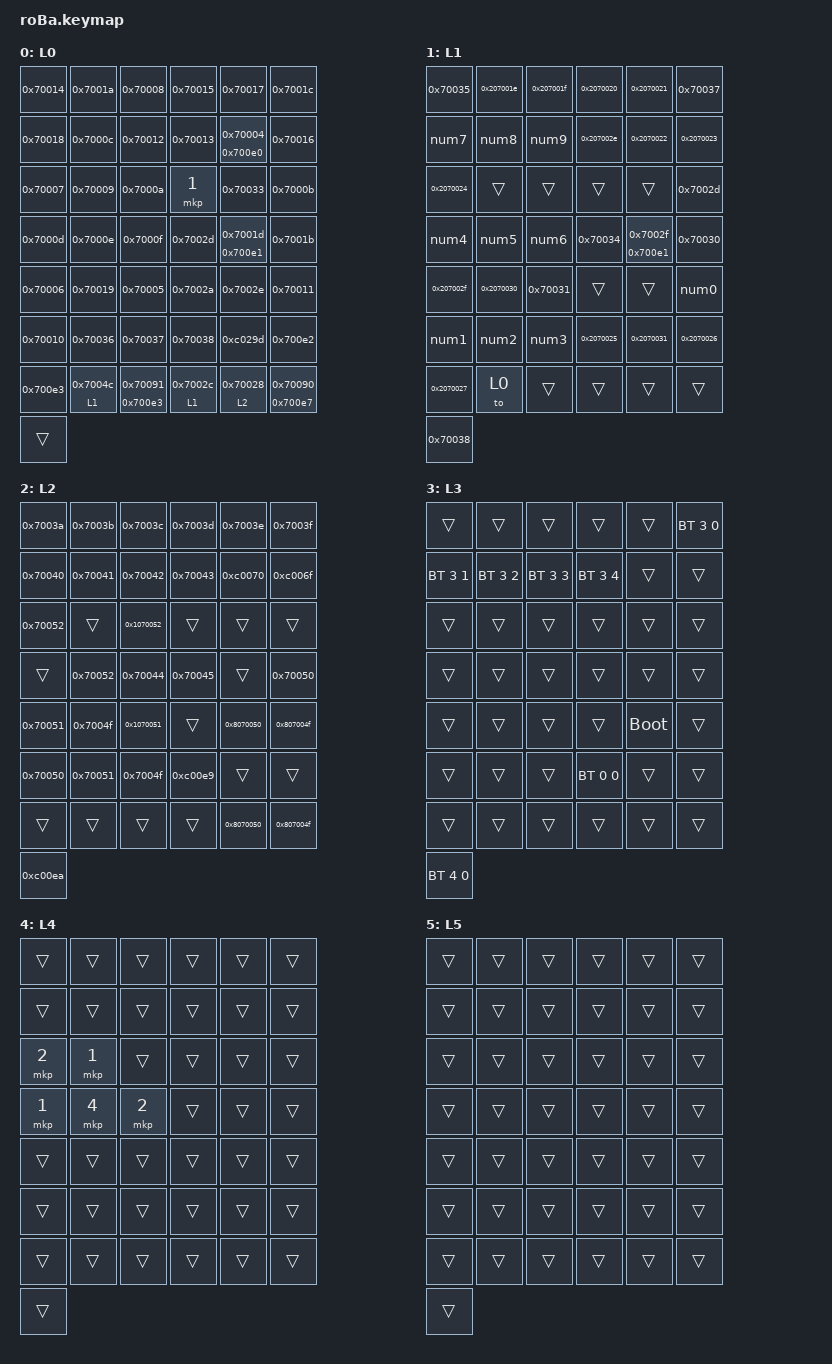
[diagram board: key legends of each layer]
/*
 * roBa (Low Profile) キーマップ
 * 出品者ファームウェア（~/src/roba-backup/right_seller.uf2）の設定と、
 * 2026-11-15 時点で ZMK Studio から読んだ配置をもとに tools/gen_keymap.py で作る。
 */
#include <behaviors.dtsi>
#include <dt-bindings/zmk/bt.h>
#include <dt-bindings/zmk/keys.h>
#include <dt-bindings/zmk/pointing.h>

/* 長押しの判定（出品者: 180 ms, tap-preferred, quick-tap 150 ms） */
&mt { flavor = "tap-preferred"; tapping-term-ms = <220>; quick-tap-ms = <150>; };
&lt { flavor = "tap-preferred"; tapping-term-ms = <220>; quick-tap-ms = <150>; };

&trackball {
    automouse-layer = <4>;
    scroll-layers = <5>;    /* D＋F・J＋K を押し続けている間はスクロール */
};

/ {
    behaviors {
        /* A・Z 用: 直前のキーから 150 ms 以内は必ず文字として扱う */
        mt_key: mt_key {
            compatible = "zmk,behavior-hold-tap";
            label = "MT_KEY";
            display-name = "Mod-Tap (文字キー)";
            #binding-cells = <2>;
            bindings = <&kp>, <&kp>;
            flavor = "tap-preferred";
            tapping-term-ms = <220>;
            quick-tap-ms = <150>;
            require-prior-idle-ms = <150>;
        };

        lt_to_layer_0: lt_to_layer_0 {
            compatible = "zmk,behavior-hold-tap";
            label = "LAYER_TAP_TO_0";
            display-name = "LAYER_TAP_TO_0";
            #binding-cells = <2>;
            bindings = <&mo>, <&to_layer_0>;
            flavor = "hold-preferred";
            tapping-term-ms = <180>;
        };

        /* D＋F・J＋K 用: 短く押すと Shift＋Tab・Enter、押し続けるとレイヤー 5（トラックボールでスクロール） */
        tap_scroll: tap_scroll {
            compatible = "zmk,behavior-hold-tap";
            label = "TAP_SCROLL";
            display-name = "キー / スクロール";
            #binding-cells = <2>;
            bindings = <&mo>, <&kp>;
            flavor = "hold-preferred";
            tapping-term-ms = <200>;
        };

        mouse_command: mouse_command {
            compatible = "zmk,behavior-hold-tap";
            label = "MOUSE_COMMAND";
            display-name = "MOUSE_COMMAND";
            #binding-cells = <2>;
            bindings = <&kp>, <&mkp>;
            flavor = "tap-preferred";
            tapping-term-ms = <180>;
        };

        alt_tab_rotate: alt_tab_rotate {
            compatible = "zmk,behavior-sensor-rotate";
            label = "ALT_TAB_ROTATE";
            #sensor-binding-cells = <0>;
            bindings = <&kp 0x0c070050>, <&kp 0x0c07004f>;
            tap-ms = <20>;
        };

        enc_msc_down_up: enc_msc_down_up {
            compatible = "zmk,behavior-sensor-rotate";
            label = "ENCODER_MSC_DOWN_UP";
            #sensor-binding-cells = <0>;
            bindings = <&msc MOVE_Y(-80)>, <&msc MOVE_Y(80)>;
            tap-ms = <20>;
        };

        enc_key_press: enc_key_press {
            compatible = "zmk,behavior-sensor-rotate-var";
            label = "enc_key_press";
            #sensor-binding-cells = <2>;
            bindings = <&kp>, <&kp>;
            tap-ms = <5>;
        };

        num0: num0 {
            compatible = "zmk,behavior-mod-morph";
            display-name = "数字0";
            #binding-cells = <0>;
            bindings = <&kp 0x70062>, <&kp 0x70027>;
            mods = <(MOD_LGUI|MOD_RGUI|MOD_LCTL|MOD_RCTL|MOD_LALT|MOD_RALT)>;
            keep-mods = <(MOD_LGUI|MOD_RGUI|MOD_LCTL|MOD_RCTL|MOD_LALT|MOD_RALT)>;
        };

        num1: num1 {
            compatible = "zmk,behavior-mod-morph";
            display-name = "数字1";
            #binding-cells = <0>;
            bindings = <&kp 0x70059>, <&kp 0x7001e>;
            mods = <(MOD_LGUI|MOD_RGUI|MOD_LCTL|MOD_RCTL|MOD_LALT|MOD_RALT)>;
            keep-mods = <(MOD_LGUI|MOD_RGUI|MOD_LCTL|MOD_RCTL|MOD_LALT|MOD_RALT)>;
        };

        num2: num2 {
            compatible = "zmk,behavior-mod-morph";
            display-name = "数字2";
            #binding-cells = <0>;
            bindings = <&kp 0x7005a>, <&kp 0x7001f>;
            mods = <(MOD_LGUI|MOD_RGUI|MOD_LCTL|MOD_RCTL|MOD_LALT|MOD_RALT)>;
            keep-mods = <(MOD_LGUI|MOD_RGUI|MOD_LCTL|MOD_RCTL|MOD_LALT|MOD_RALT)>;
        };

        num3: num3 {
            compatible = "zmk,behavior-mod-morph";
            display-name = "数字3";
            #binding-cells = <0>;
            bindings = <&kp 0x7005b>, <&kp 0x70020>;
            mods = <(MOD_LGUI|MOD_RGUI|MOD_LCTL|MOD_RCTL|MOD_LALT|MOD_RALT)>;
            keep-mods = <(MOD_LGUI|MOD_RGUI|MOD_LCTL|MOD_RCTL|MOD_LALT|MOD_RALT)>;
        };

        num4: num4 {
            compatible = "zmk,behavior-mod-morph";
            display-name = "数字4";
            #binding-cells = <0>;
            bindings = <&kp 0x7005c>, <&kp 0x70021>;
            mods = <(MOD_LGUI|MOD_RGUI|MOD_LCTL|MOD_RCTL|MOD_LALT|MOD_RALT)>;
            keep-mods = <(MOD_LGUI|MOD_RGUI|MOD_LCTL|MOD_RCTL|MOD_LALT|MOD_RALT)>;
        };

        num5: num5 {
            compatible = "zmk,behavior-mod-morph";
            display-name = "数字5";
            #binding-cells = <0>;
            bindings = <&kp 0x7005d>, <&kp 0x70022>;
            mods = <(MOD_LGUI|MOD_RGUI|MOD_LCTL|MOD_RCTL|MOD_LALT|MOD_RALT)>;
            keep-mods = <(MOD_LGUI|MOD_RGUI|MOD_LCTL|MOD_RCTL|MOD_LALT|MOD_RALT)>;
        };

        num6: num6 {
            compatible = "zmk,behavior-mod-morph";
            display-name = "数字6";
            #binding-cells = <0>;
            bindings = <&kp 0x7005e>, <&kp 0x70023>;
            mods = <(MOD_LGUI|MOD_RGUI|MOD_LCTL|MOD_RCTL|MOD_LALT|MOD_RALT)>;
            keep-mods = <(MOD_LGUI|MOD_RGUI|MOD_LCTL|MOD_RCTL|MOD_LALT|MOD_RALT)>;
        };

        num7: num7 {
            compatible = "zmk,behavior-mod-morph";
            display-name = "数字7";
            #binding-cells = <0>;
            bindings = <&kp 0x7005f>, <&kp 0x70024>;
            mods = <(MOD_LGUI|MOD_RGUI|MOD_LCTL|MOD_RCTL|MOD_LALT|MOD_RALT)>;
            keep-mods = <(MOD_LGUI|MOD_RGUI|MOD_LCTL|MOD_RCTL|MOD_LALT|MOD_RALT)>;
        };

        num8: num8 {
            compatible = "zmk,behavior-mod-morph";
            display-name = "数字8";
            #binding-cells = <0>;
            bindings = <&kp 0x70060>, <&kp 0x70025>;
            mods = <(MOD_LGUI|MOD_RGUI|MOD_LCTL|MOD_RCTL|MOD_LALT|MOD_RALT)>;
            keep-mods = <(MOD_LGUI|MOD_RGUI|MOD_LCTL|MOD_RCTL|MOD_LALT|MOD_RALT)>;
        };

        num9: num9 {
            compatible = "zmk,behavior-mod-morph";
            display-name = "数字9";
            #binding-cells = <0>;
            bindings = <&kp 0x70061>, <&kp 0x70026>;
            mods = <(MOD_LGUI|MOD_RGUI|MOD_LCTL|MOD_RCTL|MOD_LALT|MOD_RALT)>;
            keep-mods = <(MOD_LGUI|MOD_RGUI|MOD_LCTL|MOD_RCTL|MOD_LALT|MOD_RALT)>;
        };
    };

    macros {
        to_layer_0: to_layer_0 {
            compatible = "zmk,behavior-macro-one-param";
            label = "TO_LAYER_0";
            display-name = "TO_LAYER_0";
            #binding-cells = <1>;
            bindings = <&to 0 &macro_param_1to1 &kp MACRO_PLACEHOLDER>;
        };
    };

    /* BS（L1）と Enter（L2）を同時に長押しすると Bluetooth のレイヤー 3 */
    conditional_layers {
        compatible = "zmk,conditional-layers";
        bluetooth {
            if-layers = <1 2>;
            then-layer = <3>;
        };
    };

    /* 出品者の同時押し（50 ms 以内） */
    combos {
        compatible = "zmk,combos";
        esc { timeout-ms = <50>; key-positions = <0 1>; bindings = <&to_layer_0 ESCAPE>; };
        grave { timeout-ms = <50>; key-positions = <1 2>; bindings = <&kp GRAVE>; };
        excl { timeout-ms = <50>; key-positions = <2 3>; bindings = <&kp EXCLAMATION>; };
        at { timeout-ms = <50>; key-positions = <3 4>; bindings = <&kp AT_SIGN>; };
        lpar { timeout-ms = <50>; key-positions = <6 7>; bindings = <&kp LEFT_PARENTHESIS>; };
        rpar { timeout-ms = <50>; key-positions = <7 8>; bindings = <&kp RIGHT_PARENTHESIS>; };
        bspc { timeout-ms = <50>; key-positions = <8 9>; bindings = <&kp BACKSPACE>; };
        tab { timeout-ms = <50>; key-positions = <11 12>; bindings = <&kp TAB>; };
        shift_tab { timeout-ms = <50>; key-positions = <12 13>; bindings = <&tap_scroll 5 LS(TAB)>; };
        enter_jk { timeout-ms = <50>; key-positions = <18 19>; bindings = <&tap_scroll 5 ENTER>; };
        lbkt_kl { timeout-ms = <50>; key-positions = <19 20>; bindings = <&kp LEFT_BRACKET>; };
        rbkt_ld { timeout-ms = <50>; key-positions = <20 21>; bindings = <&kp RIGHT_BRACKET>; };
    };

    keymap {
        compatible = "zmk,keymap";

        layer_0 {
            display-name = "L0";
            bindings = <
                &kp 0x70014  &kp 0x7001a  &kp 0x70008  &kp 0x70015  &kp 0x70017  &kp 0x7001c
                &kp 0x70018  &kp 0x7000c  &kp 0x70012  &kp 0x70013  &mt_key 0x700e0 0x70004  &kp 0x70016
                &kp 0x70007  &kp 0x70009  &kp 0x7000a  &mkp 1  &kp 0x70033  &kp 0x7000b
                &kp 0x7000d  &kp 0x7000e  &kp 0x7000f  &kp 0x7002d  &mt_key 0x700e1 0x7001d  &kp 0x7001b
                &kp 0x70006  &kp 0x70019  &kp 0x70005  &kp 0x7002a  &kp 0x7002e  &kp 0x70011
                &kp 0x70010  &kp 0x70036  &kp 0x70037  &kp 0x70038  &kp 0xc029d  &kp 0x700e2
                &kp 0x700e3  &lt_to_layer_0 1 0x7004c  &mt 0x700e3 0x70091  &lt 1 0x7002c  &lt 2 0x70028  &mt 0x700e7 0x70090
                &trans
            >;
            sensor-bindings = <&enc_msc_down_up>;
        };

        layer_1 {
            display-name = "L1";
            bindings = <
                &kp 0x70035  &kp 0x207001e  &kp 0x207001f  &kp 0x2070020  &kp 0x2070021  &kp 0x70037
                &num7  &num8  &num9  &kp 0x207002e  &kp 0x2070022  &kp 0x2070023
                &kp 0x2070024  &trans  &trans  &trans  &trans  &kp 0x7002d
                &num4  &num5  &num6  &kp 0x70034  &mt 0x700e1 0x7002f  &kp 0x70030
                &kp 0x207002f  &kp 0x2070030  &kp 0x70031  &trans  &trans  &num0
                &num1  &num2  &num3  &kp 0x2070025  &kp 0x2070031  &kp 0x2070026
                &kp 0x2070027  &to 0  &trans  &trans  &trans  &trans
                &kp 0x70038
            >;
        };

        layer_2 {
            display-name = "L2";
            bindings = <
                &kp 0x7003a  &kp 0x7003b  &kp 0x7003c  &kp 0x7003d  &kp 0x7003e  &kp 0x7003f
                &kp 0x70040  &kp 0x70041  &kp 0x70042  &kp 0x70043  &kp 0xc0070  &kp 0xc006f
                &kp 0x70052  &trans  &kp 0x1070052  &trans  &trans  &trans
                &trans  &kp 0x70052  &kp 0x70044  &kp 0x70045  &trans  &kp 0x70050
                &kp 0x70051  &kp 0x7004f  &kp 0x1070051  &trans  &kp 0x8070050  &kp 0x807004f
                &kp 0x70050  &kp 0x70051  &kp 0x7004f  &kp 0xc00e9  &trans  &trans
                &trans  &trans  &trans  &trans  &kp 0x8070050  &kp 0x807004f
                &kp 0xc00ea
            >;
            sensor-bindings = <&enc_key_press 0xc00e9 0xc00ea>;
        };

        layer_3 {
            display-name = "L3";
            bindings = <
                &trans  &trans  &trans  &trans  &trans  &bt 3 0
                &bt 3 1  &bt 3 2  &bt 3 3  &bt 3 4  &trans  &trans
                &trans  &trans  &trans  &trans  &trans  &trans
                &trans  &trans  &trans  &trans  &trans  &trans
                &trans  &trans  &trans  &trans  &bootloader  &trans
                &trans  &trans  &trans  &bt 0 0  &trans  &trans
                &trans  &trans  &trans  &trans  &trans  &trans
                &bt 4 0
            >;
        };

        layer_4 {
            display-name = "L4";
            bindings = <
                &trans  &trans  &trans  &trans  &trans  &trans
                &trans  &trans  &trans  &trans  &trans  &trans
                &mkp 2  &mkp 1  &trans  &trans  &trans  &trans
                &mkp 1  &mkp 4  &mkp 2  &trans  &trans  &trans
                &trans  &trans  &trans  &trans  &trans  &trans
                &trans  &trans  &trans  &trans  &trans  &trans
                &trans  &trans  &trans  &trans  &trans  &trans
                &trans
            >;
            sensor-bindings = <&enc_msc_down_up>;
        };

        layer_5 {
            display-name = "L5";
            bindings = <
                &trans  &trans  &trans  &trans  &trans  &trans
                &trans  &trans  &trans  &trans  &trans  &trans
                &trans  &trans  &trans  &trans  &trans  &trans
                &trans  &trans  &trans  &trans  &trans  &trans
                &trans  &trans  &trans  &trans  &trans  &trans
                &trans  &trans  &trans  &trans  &trans  &trans
                &trans  &trans  &trans  &trans  &trans  &trans
                &trans
            >;
        };
    };
};
